# CC27x0 register map
File version: 1.0
CPU: CM4 r0p4, little endian, no MPU, no FPU, VTOR, 3 interrupt priority bits
Registers are 32-bit, read-write, reset 0x0 unless marked. A register's access mark holds for its fields unless they carry their own. Offsets are from the block's base; [hi:lo] are bit positions; {n}, {i} and the like mark numbered series; 'fields as' and 'values as' point back to an identical list.

## LRFDPBE
Base 0x40081000
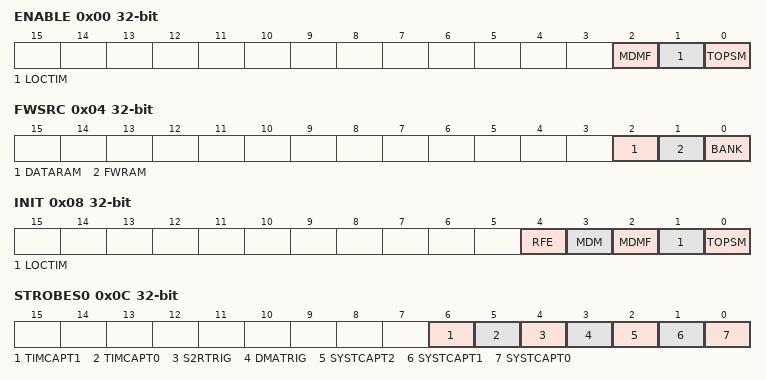
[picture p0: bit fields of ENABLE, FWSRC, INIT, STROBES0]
0x00 ENABLE — Internal. Only to be used through TI provided API.
  [all] fields
    1=EN (Internal. Only to be used through TI provided API.); 0=DIS (Internal. Only to be used through TI provided API.)
  [2] MDMF — Internal. Only to be used through TI provided API.
  [1] LOCTIM — Internal. Only to be used through TI provided API.
  [0] TOPSM — Internal. Only to be used through TI provided API.
0x04 FWSRC — Internal. Only to be used through TI provided API.
  [2] DATARAM — Internal. Only to be used through TI provided API.
    1=S2RRAM (Internal. Only to be used through TI provided API.); 0=PBERAM (Internal. Only to be used through TI provided API.)
  [1] FWRAM — Internal. Only to be used through TI provided API.
    values as DATARAM
  [0] BANK — Internal. Only to be used through TI provided API.
    1=ONE (Internal. Only to be used through TI provided API.); 0=ZERO (Internal. Only to be used through TI provided API.)
0x08 INIT wo — Internal. Only to be used through TI provided API.
  [all] fields
    1=RESET (Internal. Only to be used through TI provided API.); 0=NO_EFFECT (Internal. Only to be used through TI provided API.)
  [4] RFE — Internal. Only to be used through TI provided API.
  [3] MDM — Internal. Only to be used through TI provided API.
  [2] MDMF — Internal. Only to be used through TI provided API.
  [1] LOCTIM — Internal. Only to be used through TI provided API.
  [0] TOPSM — Internal. Only to be used through TI provided API.
0x0C STROBES0 wo — Internal. Only to be used through TI provided API.
  [6] TIMCAPT1 — Internal. Only to be used through TI provided API.
    values as FWSRC.BANK
  [5] TIMCAPT0 — Internal. Only to be used through TI provided API.
    values as FWSRC.BANK
  [4] S2RTRIG — Internal. Only to be used through TI provided API.
    1=ARM (Internal. Only to be used through TI provided API.); 0=NO_EFFECT (Internal. Only to be used through TI provided API.)
  [3] DMATRIG — Internal. Only to be used through TI provided API.
    values as S2RTRIG
  [2] SYSTCAPT2 — Internal. Only to be used through TI provided API.
    values as FWSRC.BANK
  [1] SYSTCAPT1 — Internal. Only to be used through TI provided API.
    values as FWSRC.BANK
  [0] SYSTCAPT0 — Internal. Only to be used through TI provided API.
    values as FWSRC.BANK
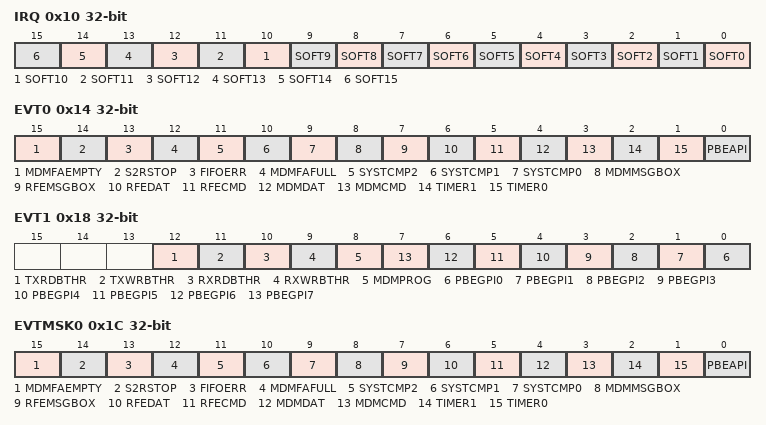
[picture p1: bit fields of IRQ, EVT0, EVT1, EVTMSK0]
0x10 IRQ wo — Internal. Only to be used through TI provided API.
  [all] fields
    1=ON (Internal. Only to be used through TI provided API.); 0=OFF (Internal. Only to be used through TI provided API.)
  [n] SOFT{n} (n=0..15) — Internal. Only to be used through TI provided API.
0x14 EVT0 ro — Internal. Only to be used through TI provided API.
  [all] fields
    values as FWSRC.BANK
  [15] MDMFAEMPTY — Internal. Only to be used through TI provided API.
  [14] S2RSTOP — Internal. Only to be used through TI provided API.
  [13] FIFOERR — Internal. Only to be used through TI provided API.
  [12] MDMFAFULL — Internal. Only to be used through TI provided API.
  [11] SYSTCMP2 — Internal. Only to be used through TI provided API.
  [10] SYSTCMP1 — Internal. Only to be used through TI provided API.
  [9] SYSTCMP0 — Internal. Only to be used through TI provided API.
  [8] MDMMSGBOX — Internal. Only to be used through TI provided API.
  [7] RFEMSGBOX — Internal. Only to be used through TI provided API.
  [6] RFEDAT — Internal. Only to be used through TI provided API.
  [5] RFECMD — Internal. Only to be used through TI provided API.
  [4] MDMDAT — Internal. Only to be used through TI provided API.
  [3] MDMCMD — Internal. Only to be used through TI provided API.
  [2] TIMER1 — Internal. Only to be used through TI provided API.
  [1] TIMER0 — Internal. Only to be used through TI provided API.
  [0] PBEAPI — Internal. Only to be used through TI provided API.
0x18 EVT1 ro — Internal. Only to be used through TI provided API.
  [12] TXRDBTHR — Internal. Only to be used through TI provided API.
    1=MET (Internal. Only to be used through TI provided API.); 0=BELOW (Internal. Only to be used through TI provided API.)
  [11] TXWRBTHR — Internal. Only to be used through TI provided API.
    values as TXRDBTHR
  [10] RXRDBTHR — Internal. Only to be used through TI provided API.
    values as TXRDBTHR
  [9] RXWRBTHR — Internal. Only to be used through TI provided API.
    values as TXRDBTHR
  [8] MDMPROG — Internal. Only to be used through TI provided API.
    values as FWSRC.BANK
  [n] PBEGPI{n} (n=0..7) — Internal. Only to be used through TI provided API.
    values as FWSRC.BANK
0x1C EVTMSK0 — Internal. Only to be used through TI provided API.
  [all] fields
    values as the fields of ENABLE
  [15] MDMFAEMPTY — Internal. Only to be used through TI provided API.
  [14] S2RSTOP — Internal. Only to be used through TI provided API.
  [13] FIFOERR — Internal. Only to be used through TI provided API.
  [12] MDMFAFULL — Internal. Only to be used through TI provided API.
  [11] SYSTCMP2 — Internal. Only to be used through TI provided API.
  [10] SYSTCMP1 — Internal. Only to be used through TI provided API.
  [9] SYSTCMP0 — Internal. Only to be used through TI provided API.
  [8] MDMMSGBOX — Internal. Only to be used through TI provided API.
  [7] RFEMSGBOX — Internal. Only to be used through TI provided API.
  [6] RFEDAT — Internal. Only to be used through TI provided API.
  [5] RFECMD — Internal. Only to be used through TI provided API.
  [4] MDMDAT — Internal. Only to be used through TI provided API.
  [3] MDMCMD — Internal. Only to be used through TI provided API.
  [2] TIMER1 — Internal. Only to be used through TI provided API.
  [1] TIMER0 — Internal. Only to be used through TI provided API.
  [0] PBEAPI — Internal. Only to be used through TI provided API.
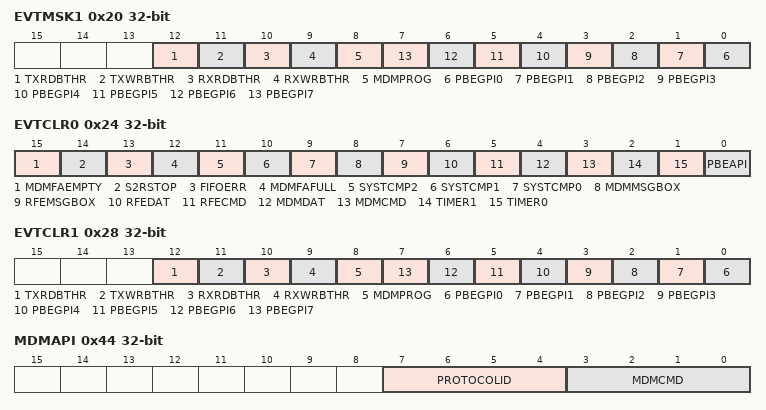
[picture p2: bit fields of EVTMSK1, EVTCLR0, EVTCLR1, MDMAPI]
0x20 EVTMSK1 — Internal. Only to be used through TI provided API.
  [all] fields
    values as the fields of ENABLE
  [12] TXRDBTHR — Internal. Only to be used through TI provided API.
  [11] TXWRBTHR — Internal. Only to be used through TI provided API.
  [10] RXRDBTHR — Internal. Only to be used through TI provided API.
  [9] RXWRBTHR — Internal. Only to be used through TI provided API.
  [8] MDMPROG — Internal. Only to be used through TI provided API.
  [n] PBEGPI{n} (n=0..7) — Internal. Only to be used through TI provided API.
0x24 EVTCLR0 wo — Internal. Only to be used through TI provided API.
  [all] fields
    1=CLEAR (Internal. Only to be used through TI provided API.); 0=RETAIN (Internal. Only to be used through TI provided API.)
  [15] MDMFAEMPTY — Internal. Only to be used through TI provided API.
  [14] S2RSTOP — Internal. Only to be used through TI provided API.
  [13] FIFOERR — Internal. Only to be used through TI provided API.
  [12] MDMFAFULL — Internal. Only to be used through TI provided API.
  [11] SYSTCMP2 — Internal. Only to be used through TI provided API.
  [10] SYSTCMP1 — Internal. Only to be used through TI provided API.
  [9] SYSTCMP0 — Internal. Only to be used through TI provided API.
  [8] MDMMSGBOX — Internal. Only to be used through TI provided API.
  [7] RFEMSGBOX — Internal. Only to be used through TI provided API.
  [6] RFEDAT — Internal. Only to be used through TI provided API.
  [5] RFECMD — Internal. Only to be used through TI provided API.
  [4] MDMDAT — Internal. Only to be used through TI provided API.
  [3] MDMCMD — Internal. Only to be used through TI provided API.
  [2] TIMER1 — Internal. Only to be used through TI provided API.
  [1] TIMER0 — Internal. Only to be used through TI provided API.
  [0] PBEAPI — Internal. Only to be used through TI provided API.
0x28 EVTCLR1 wo — Internal. Only to be used through TI provided API.
  [all] fields
    values as the fields of EVTCLR0
  [12] TXRDBTHR — Internal. Only to be used through TI provided API.
  [11] TXWRBTHR — Internal. Only to be used through TI provided API.
  [10] RXRDBTHR — Internal. Only to be used through TI provided API.
  [9] RXWRBTHR — Internal. Only to be used through TI provided API.
  [8] MDMPROG — Internal. Only to be used through TI provided API.
  [n] PBEGPI{n} (n=0..7) — Internal. Only to be used through TI provided API.
0x2C PDREQ — Internal. Only to be used through TI provided API.
  [0] TOPSMPDREQ
    values as the fields of IRQ
0x30 API — Internal. Only to be used through TI provided API.
  [4:0] PBECMD
    31=ALLONES (Internal. Only to be used through TI provided API.); 0=ALLZEROS (Internal. Only to be used through TI provided API.)
0x34 MCEDATOUT0 — Internal. Only to be used through TI provided API.
  [15:0] VAL
    0xFFFF=ALLONES (Internal. Only to be used through TI provided API.); 0=ALLZEROS (Internal. Only to be used through TI provided API.)
0x38 MCEDATIN0 ro — Internal. Only to be used through TI provided API.
  fields as MCEDATOUT0
0x3C MCECMDOUT — Internal. Only to be used through TI provided API.
  [3:0] VAL
    15=ALLONES (Internal. Only to be used through TI provided API.); 0=ALLZEROS (Internal. Only to be used through TI provided API.)
0x40 MCECMDIN ro — Internal. Only to be used through TI provided API.
  fields as MCECMDOUT
0x44 MDMAPI — Internal. Only to be used through TI provided API.
  [7:4] PROTOCOLID — Internal. Only to be used through TI provided API.
    values as MCECMDOUT.VAL
  [3:0] MDMCMD — Internal. Only to be used through TI provided API.
    values as MCECMDOUT.VAL
0x48 MDMMSGBOX ro — Internal. Only to be used through TI provided API.
  [7:0] VALUE
    255=ALLONES (Internal. Only to be used through TI provided API.); 0=ALLZEROS (Internal. Only to be used through TI provided API.)
0x4C FREQ ro — Internal. Only to be used through TI provided API.
  [15:0] OFFSET
    values as MCEDATOUT0.VAL
0x50 MDMLQI ro — Internal. Only to be used through TI provided API.
  [7:0] VAL
    values as MDMMSGBOX.VALUE
0x54 RFEDATOUT0 — Internal. Only to be used through TI provided API.
  fields as MCEDATOUT0
0x58 RFEDATIN0 ro — Internal. Only to be used through TI provided API.
  fields as MCEDATOUT0
0x5C RFECMDOUT — Internal. Only to be used through TI provided API.
  fields as MCECMDOUT
0x60 RFECMDIN ro — Internal. Only to be used through TI provided API.
  fields as MCECMDOUT
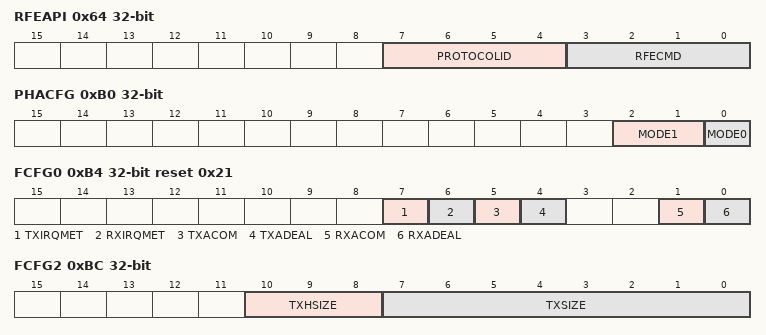
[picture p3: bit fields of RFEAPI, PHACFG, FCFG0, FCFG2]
0x64 RFEAPI — Internal. Only to be used through TI provided API.
  [7:4] PROTOCOLID — Internal. Only to be used through TI provided API.
    values as MCECMDOUT.VAL
  [3:0] RFECMD — Internal. Only to be used through TI provided API.
    values as MCECMDOUT.VAL
0x68 RFECMDPAR0 — Internal. Only to be used through TI provided API.
  fields as MCEDATOUT0
0x6C RFECMDPAR1 — Internal. Only to be used through TI provided API.
  fields as MCEDATOUT0
0x70 RFEMSGBOX ro — Internal. Only to be used through TI provided API.
  fields as MDMLQI
0x74 RFERSSI ro — Internal. Only to be used through TI provided API.
  fields as MDMLQI
0x78 RFERSSIMAX ro — Internal. Only to be used through TI provided API.
  fields as MDMLQI
0x7C RFERFGAIN ro — Internal. Only to be used through TI provided API.
  [7:0] DBGAIN
    values as MDMMSGBOX.VALUE
0x80 MDMSYNCAL — Internal. Only to be used through TI provided API.
  [15:0] SWALSB
    values as MCEDATOUT0.VAL
0x84 MDMSYNCAH — Internal. Only to be used through TI provided API.
  [15:0] SWAMSB
    values as MCEDATOUT0.VAL
0x88 MDMSYNCBL — Internal. Only to be used through TI provided API.
  [15:0] SWBLSB
    values as MCEDATOUT0.VAL
0x8C MDMSYNCBH — Internal. Only to be used through TI provided API.
  [15:0] SWBMSB
    values as MCEDATOUT0.VAL
{0x90+4i} MDMCMDPAR{i} (i=0..2) — Internal. Only to be used through TI provided API.
  fields as MCEDATOUT0
0x9C RFEDATIN1 ro — Internal. Only to be used through TI provided API.
  fields as MCEDATOUT0
0xA0 POLY0L — Internal. Only to be used through TI provided API.
  [15:0] VALLSB
    values as MCEDATOUT0.VAL
0xA4 POLY0H — Internal. Only to be used through TI provided API.
  [15:0] VALMSB
    values as MCEDATOUT0.VAL
0xA8 POLY1L — Internal. Only to be used through TI provided API.
  fields as POLY0L
0xAC POLY1H — Internal. Only to be used through TI provided API.
  fields as POLY0H
0xB0 PHACFG — Internal. Only to be used through TI provided API.
  [2:1] MODE1 — Internal. Only to be used through TI provided API.
    2=PARAL (Internal. Only to be used through TI provided API.); 1=CASC (Internal. Only to be used through TI provided API.); 0=INDEP (Internal. Only to be used through TI provided API.)
  [0] MODE0 — Internal. Only to be used through TI provided API.
    1=WHITE (Internal. Only to be used through TI provided API.); 0=CRC (Internal. Only to be used through TI provided API.)
0xB4 FCFG0 reset 0x21 — Internal. Only to be used through TI provided API.
  [7] TXIRQMET — Internal. Only to be used through TI provided API.
    1=TXRDBTHR (Internal. Only to be used through TI provided API.); 0=TXWRBTHR (Internal. Only to be used through TI provided API.)
  [6] RXIRQMET — Internal. Only to be used through TI provided API.
    1=RXWRBTHR (Internal. Only to be used through TI provided API.); 0=RXRDBTHR (Internal. Only to be used through TI provided API.)
  [5] TXACOM — Internal. Only to be used through TI provided API.
    values as the fields of ENABLE
  [4] TXADEAL — Internal. Only to be used through TI provided API.
    values as the fields of ENABLE
  [1] RXACOM — Internal. Only to be used through TI provided API.
    values as the fields of ENABLE
  [0] RXADEAL — Internal. Only to be used through TI provided API.
    values as the fields of ENABLE
0xB8 FCFG1 — Internal. Only to be used through TI provided API.
  [8:0] TXSTRT
    0x1FF=ONES (Internal. Only to be used through TI provided API.); 0=ZEROS (Internal. Only to be used through TI provided API.)
0xBC FCFG2 — Internal. Only to be used through TI provided API.
  [10:8] TXHSIZE — Internal. Only to be used through TI provided API.
    2=WORD (Internal. Only to be used through TI provided API.); 1=HALFW (Internal. Only to be used through TI provided API.); 0=BYTE (Internal. Only to be used through TI provided API.)
  [7:0] TXSIZE — Internal. Only to be used through TI provided API.
    255=ONES (Internal. Only to be used through TI provided API.); 0=ZEROS (Internal. Only to be used through TI provided API.)
0xC0 FCFG3 — Internal. Only to be used through TI provided API.
  [8:0] RXSTRT
    values as FCFG1.TXSTRT
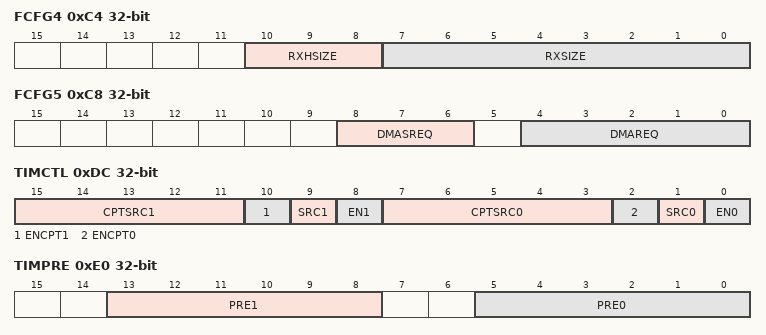
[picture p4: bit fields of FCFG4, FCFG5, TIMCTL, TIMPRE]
0xC4 FCFG4 — Internal. Only to be used through TI provided API.
  [10:8] RXHSIZE — Internal. Only to be used through TI provided API.
    values as FCFG2.TXHSIZE
  [7:0] RXSIZE — Internal. Only to be used through TI provided API.
    values as FCFG2.TXSIZE
0xC8 FCFG5 — Internal. Only to be used through TI provided API.
  [8:6] DMASREQ — Internal. Only to be used through TI provided API.
    4=TXFIFOFREE (Internal. Only to be used through TI provided API.); 3=TXFIFOMD (Internal. Only to be used through TI provided API.); 2=RXFIFOFREE (Internal. Only to be used through TI provided API.); 1=RXFIFOMD (Internal. Only to be used through TI provided API.); 0=NONE (Internal. Only to be used through TI provided API.)
  [4:0] DMAREQ — Internal. Only to be used through TI provided API.
    15=TXFIFO_COMMIT (Internal. Only to be used through TI provided API.); 14=TXFIFO_DISCARD (Internal. Only to be used through TI provided API.); 13=TXFIFO_RETRY (Internal. Only to be used through TI provided API.); 12=TXFIFO_DEALLOC (Internal. Only to be used through TI provided API.); 11=TXFIFO_RESET (Internal. Only to be used through TI provided API.); 10=TXWRBTHR_MET (Internal. Only to be used through TI provided API.); 9=TXRDBTHR_MET (Internal. Only to be used through TI provided API.); 7=RXFIFO_COMMIT (Internal. Only to be used through TI provided API.); 6=RXFIFO_DISCARD (Internal. Only to be used through TI provided API.); 5=RXFIFO_RETRY (Internal. Only to be used through TI provided API.); 4=RXFIFO_DEALLOC (Internal. Only to be used through TI provided API.); 3=RXFIFO_RESET (Internal. Only to be used through TI provided API.); 2=RXWRBTHR_MET (Internal. Only to be used through TI provided API.); 1=RXRDBTHR_MET (Internal. Only to be used through TI provided API.); 0=NONE (Internal. Only to be used through TI provided API.)
0xCC RXFWBTHRS — Internal. Only to be used through TI provided API.
  [9:0] BYTES
    0x3FF=ALLONES (Internal. Only to be used through TI provided API.); 0=ALLZEROS (Internal. Only to be used through TI provided API.)
0xD0 RXFRBTHRS — Internal. Only to be used through TI provided API.
  fields as RXFWBTHRS
0xD4 TXFWBTHRS — Internal. Only to be used through TI provided API.
  fields as RXFWBTHRS
0xD8 TXFRBTHRS — Internal. Only to be used through TI provided API.
  fields as RXFWBTHRS
0xDC TIMCTL — Internal. Only to be used through TI provided API.
  [15:11] CPTSRC1 — Internal. Only to be used through TI provided API.
    values as API.PBECMD
  [10] ENCPT1 — Internal. Only to be used through TI provided API.
    values as the fields of IRQ
  [9] SRC1 — Internal. Only to be used through TI provided API.
    1=PRE1 (Internal. Only to be used through TI provided API.); 0=CLK (Internal. Only to be used through TI provided API.)
  [8] EN1 — Internal. Only to be used through TI provided API.
    values as the fields of IRQ
  [7:3] CPTSRC0 — Internal. Only to be used through TI provided API.
    values as API.PBECMD
  [2] ENCPT0 — Internal. Only to be used through TI provided API.
    values as the fields of IRQ
  [1] SRC0 — Internal. Only to be used through TI provided API.
    1=PRE0 (Internal. Only to be used through TI provided API.); 0=CLK (Internal. Only to be used through TI provided API.)
  [0] EN0 — Internal. Only to be used through TI provided API.
    values as the fields of IRQ
0xE0 TIMPRE — Internal. Only to be used through TI provided API.
  [13:8] PRE1 — Internal. Only to be used through TI provided API.
    63=DIV64 (Internal. Only to be used through TI provided API.); 0=NO_DIV (Internal. Only to be used through TI provided API.)
  [5:0] PRE0 — Internal. Only to be used through TI provided API.
    values as PRE1
0xE4 TIMPER0 — Internal. Only to be used through TI provided API.
  fields as MCEDATOUT0
0xE8 TIMPER1 — Internal. Only to be used through TI provided API.
  fields as MCEDATOUT0
0xEC TIMCAPT0 ro — Internal. Only to be used through TI provided API.
  [15:0] VALUE
    values as MCEDATOUT0.VAL
0xF0 TIMCAPT1 ro — Internal. Only to be used through TI provided API.
  fields as TIMCAPT0
0xF4 TRCCTL wo — Internal. Only to be used through TI provided API.
  [0] SEND
    values as FWSRC.BANK
0xF8 TRCSTAT ro — Internal. Only to be used through TI provided API.
  [0] BUSY
    values as FWSRC.BANK
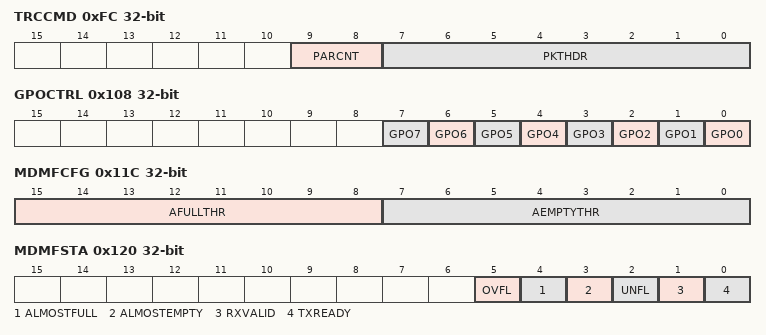
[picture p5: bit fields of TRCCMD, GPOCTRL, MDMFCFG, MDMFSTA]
0xFC TRCCMD — Internal. Only to be used through TI provided API.
  [9:8] PARCNT — Internal. Only to be used through TI provided API.
    3=ALLONES (Internal. Only to be used through TI provided API.); 0=ALLZEROS (Internal. Only to be used through TI provided API.)
  [7:0] PKTHDR — Internal. Only to be used through TI provided API.
    values as MDMMSGBOX.VALUE
0x100 TRCPAR0 — Internal. Only to be used through TI provided API.
  fields as MCEDATOUT0
0x104 TRCPAR1 — Internal. Only to be used through TI provided API.
  fields as MCEDATOUT0
0x108 GPOCTRL — Internal. Only to be used through TI provided API.
  [all] fields
    values as FWSRC.BANK
  [n] GPO{n} (n=0..7) — Internal. Only to be used through TI provided API.
0x10C MDMFWR — Internal. Only to be used through TI provided API.
  [15:0] PAYLOADIN
    values as MCEDATOUT0.VAL
0x110 MDMFRD ro — Internal. Only to be used through TI provided API.
  [15:0] PAYLOADOUT
    values as MCEDATOUT0.VAL
0x114 MDMFWRCTL — Internal. Only to be used through TI provided API.
  [3:0] WORDSZWR
    {v}=BITS{v+1} (Internal. Only to be used through TI provided API.) (v=0..15)
0x118 MDMFRDCTL — Internal. Only to be used through TI provided API.
  [3:0] WORDSZRD
    values as MDMFWRCTL.WORDSZWR
0x11C MDMFCFG — Internal. Only to be used through TI provided API.
  [15:8] AFULLTHR — Internal. Only to be used through TI provided API.
    values as MDMMSGBOX.VALUE
  [7:0] AEMPTYTHR — Internal. Only to be used through TI provided API.
    values as MDMMSGBOX.VALUE
0x120 MDMFSTA ro — Internal. Only to be used through TI provided API.
  [all] fields
    values as FWSRC.BANK
  [5] OVFL — Internal. Only to be used through TI provided API.
  [4] ALMOSTFULL — Internal. Only to be used through TI provided API.
  [3] ALMOSTEMPTY — Internal. Only to be used through TI provided API.
  [2] UNFL — Internal. Only to be used through TI provided API.
  [1] RXVALID — Internal. Only to be used through TI provided API.
  [0] TXREADY — Internal. Only to be used through TI provided API.
0x124 PHASTA ro — Internal. Only to be used through TI provided API.
  [1:0] BUSY
    1=BUSY (Internal. Only to be used through TI provided API.); 0=IDLE (Internal. Only to be used through TI provided API.)
0x128 LFSR0L reset 0xFFFF — Internal. Only to be used through TI provided API.
  fields as POLY0L
0x12C LFSR0H reset 0xFFFF — Internal. Only to be used through TI provided API.
  fields as POLY0H
0x130 LFSR0BRL reset 0xFFFF — Internal. Only to be used through TI provided API.
  fields as POLY0L
0x134 LFSR0BRH reset 0xFFFF — Internal. Only to be used through TI provided API.
  fields as POLY0H
0x138 LFSR1L reset 0xFFFF — Internal. Only to be used through TI provided API.
  fields as POLY0L
0x13C LFSR1H reset 0xFFFF — Internal. Only to be used through TI provided API.
  fields as POLY0H
0x140 LFSR1BRL reset 0xFFFF — Internal. Only to be used through TI provided API.
  fields as POLY0L
0x144 LFSR1BRH reset 0xFFFF — Internal. Only to be used through TI provided API.
  fields as POLY0H
0x148 LFSR0INL wo — Internal. Only to be used through TI provided API.
  [15:0] VAL
    values as TRCCMD.PARCNT
0x14C LFSR0N — Internal. Only to be used through TI provided API.
  [3:0] SIZE
    values as MCECMDOUT.VAL
0x150 LFSR0INM wo — Internal. Only to be used through TI provided API.
  [15:0] VAL
    values as FWSRC.BANK
0x154 PHAOUT0 — Internal. Only to be used through TI provided API.
  [15:0] VAL
    0xDCD7=ALLONES (Internal. Only to be used through TI provided API.); 0=ALLZEROS (Internal. Only to be used through TI provided API.)
0x158 LFSR1INL wo — Internal. Only to be used through TI provided API.
  fields as LFSR0INL
0x15C LFSR1N — Internal. Only to be used through TI provided API.
  fields as LFSR0N
0x160 LFSR1INM wo — Internal. Only to be used through TI provided API.
  fields as LFSR0INM
0x164 PHAOUT0BR ro — Internal. Only to be used through TI provided API.
  fields as MCEDATOUT0
0x168 DIVIDENDL wo — Internal. Only to be used through TI provided API.
  fields as POLY0L
0x16C DIVIDENDH wo — Internal. Only to be used through TI provided API.
  fields as POLY0H
0x170 DIVISORL — Internal. Only to be used through TI provided API.
  fields as POLY0L
0x174 DIVISORH — Internal. Only to be used through TI provided API.
  fields as POLY0H
0x178 QUOTIENTL ro — Internal. Only to be used through TI provided API.
  fields as POLY0L
0x17C QUOTIENTH ro — Internal. Only to be used through TI provided API.
  fields as POLY0H
{0x180+8i} SYSTIM{i}L ro (i=0..2) — Internal. Only to be used through TI provided API.
  [15:0] VALLSB
    values as FWSRC.BANK
{0x184+8i} SYSTIM{i}H ro (i=0..2) — Internal. Only to be used through TI provided API.
  [15:0] VALMSB
    values as FWSRC.BANK
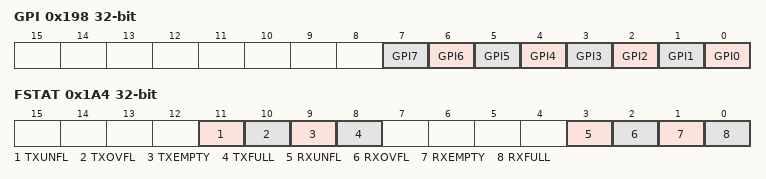
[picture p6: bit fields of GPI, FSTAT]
0x198 GPI ro — Internal. Only to be used through TI provided API.
  [all] fields
    values as FWSRC.BANK
  [n] GPI{n} (n=0..7) — Internal. Only to be used through TI provided API.
0x19C DIVSTA ro — Internal. Only to be used through TI provided API.
  [0] STAT
    values as PHASTA.BUSY
0x1A0 FCMD wo — Internal. Only to be used through TI provided API.
  [7:0] DATA
    15=FIFO_COMMIT (Internal. Only to be used through TI provided API.); 14=FIFO_DISCARD (Internal. Only to be used through TI provided API.); 13=FIFO_RETRY (Internal. Only to be used through TI provided API.); 12=FIFO_DEALLOC (Internal. Only to be used through TI provided API.); 11=FIFO_RESET (Internal. Only to be used through TI provided API.); 10=RXFIFO_RETRY (Internal. Only to be used through TI provided API.); 9=RXFIFO_DISCARD (Internal. Only to be used through TI provided API.); 8=RXFIFO_COMMIT (Internal. Only to be used through TI provided API.); 7=TXFIFO_RESET (Internal. Only to be used through TI provided API.); 6=TXFIFO_DEALLOC (Internal. Only to be used through TI provided API.); 5=TXFIFO_RETRY (Internal. Only to be used through TI provided API.); 4=TXFIFO_DISCARD (Internal. Only to be used through TI provided API.); 3=TXFIFO_COMMIT (Internal. Only to be used through TI provided API.); 2=RXFIFO_DEALLOC (Internal. Only to be used through TI provided API.); 1=RXFIFO_RESET (Internal. Only to be used through TI provided API.)
0x1A4 FSTAT ro — Internal. Only to be used through TI provided API.
  [all] fields
    1=TRUE (Internal. Only to be used through TI provided API.); 0=FALSE (Internal. Only to be used through TI provided API.)
  [11] TXUNFL — Internal. Only to be used through TI provided API.
  [10] TXOVFL — Internal. Only to be used through TI provided API.
  [9] TXEMPTY — Internal. Only to be used through TI provided API.
  [8] TXFULL — Internal. Only to be used through TI provided API.
  [3] RXUNFL — Internal. Only to be used through TI provided API.
  [2] RXOVFL — Internal. Only to be used through TI provided API.
  [1] RXEMPTY — Internal. Only to be used through TI provided API.
  [0] RXFULL — Internal. Only to be used through TI provided API.
0x1A8 RXFWP — Internal. Only to be used through TI provided API.
  [9:0] PTR
    values as RXFWBTHRS.BYTES
0x1AC RXFRP — Internal. Only to be used through TI provided API.
  fields as RXFWP
0x1B0 RXFSWP — Internal. Only to be used through TI provided API.
  fields as RXFWP
0x1B4 RXFSRP — Internal. Only to be used through TI provided API.
  fields as RXFWP
0x1B8 TXFWP — Internal. Only to be used through TI provided API.
  fields as RXFWP
0x1BC TXFRP — Internal. Only to be used through TI provided API.
  fields as RXFWP
0x1C0 TXFSWP — Internal. Only to be used through TI provided API.
  fields as RXFWP
0x1C4 TXFSRP — Internal. Only to be used through TI provided API.
  [9:0] PTR
    0x3FF=ALLONES_2 (Internal. Only to be used through TI provided API.); 0=ALLZEROS (Internal. Only to be used through TI provided API.)
0x1C8 RXFWRITABLE ro — Internal. Only to be used through TI provided API.
  fields as RXFWBTHRS
0x1CC RXFREADABLE ro — Internal. Only to be used through TI provided API.
  fields as RXFWBTHRS
0x1D0 TXFWRITABLE ro — Internal. Only to be used through TI provided API.
  fields as RXFWBTHRS
0x1D4 TXFREADABLE ro — Internal. Only to be used through TI provided API.
  fields as RXFWBTHRS
0x1D8 RXFBRD ro — Internal. Only to be used through TI provided API.
  [7:0] DATA
    values as MDMMSGBOX.VALUE
0x1DC RXFBWR wo — Internal. Only to be used through TI provided API.
  fields as RXFBRD
0x1E0 TXFBRD ro — Internal. Only to be used through TI provided API.
  fields as RXFBRD
0x1E4 TXFBWR wo — Internal. Only to be used through TI provided API.
  fields as RXFBRD
0x1E8 RXFHRD ro — Internal. Only to be used through TI provided API.
  [15:0] DATA
    values as MCEDATOUT0.VAL
0x1EC RXFHWR wo — Internal. Only to be used through TI provided API.
  fields as RXFHRD
0x1F0 TXFHRD ro — Internal. Only to be used through TI provided API.
  fields as RXFHRD
0x1F4 TXFHWR wo — Internal. Only to be used through TI provided API.
  fields as RXFHRD
0x1F8 MCEDATIN1 ro — Internal. Only to be used through TI provided API.
  fields as MCEDATOUT0
